# icc_reva_me30 register map
Registers are 32-bit, access not given, no defined reset value unless marked. A register's access mark holds for its fields unless they carry their own. Offsets are from the block's base; lines under a group give offsets from that group; [hi:lo] are bit positions; {n}, {i} and the like mark numbered series; 'fields as' and 'values as' point back to an identical list; <NAME> marks a mode.

## Memory map
0x4002A000 ICC size 0x1000 — Instruction Cache Controller Registers

## ICC — Instruction Cache Controller Registers
Base 0x4002A000
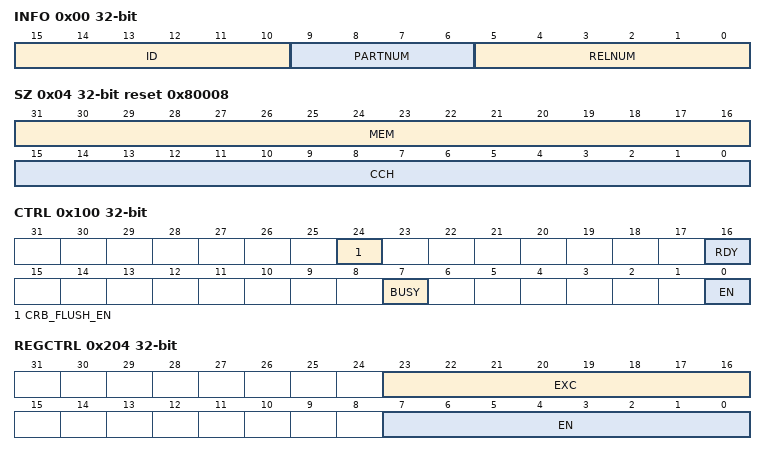
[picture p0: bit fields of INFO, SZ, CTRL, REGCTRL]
0x00 INFO ro — Cache ID Register.
  [15:10] ID — Cache ID. This field reflects the value of the C_ID_CACHEID configuration parameter.
  [9:6] PARTNUM — Part Number. This field reflects the value of C_ID_PART_NUMBER configuration parameter.
  [5:0] RELNUM — Release Number. Identifies the RTL release version.
0x04 SZ ro reset 0x80008 — Memory Configuration Register.
  [31:16] MEM — Main Memory Size. Indicates the total size, in units of 128 Kbytes, of code memory accessible to the cache controller.
  [15:0] CCH — Cache Size. Indicates total size in Kbytes of cache.
0x100 CTRL — Cache Control and Status Register.
  [24] CRB_FLUSH_EN — Coherent Read Buffer flush enable. Write 1 to flush the coherent read buffer.
  [16] RDY ro — Cache Ready flag. Cleared by hardware when at any time the cache as a whole is invalidated (including a system reset). When this bit is 0, the cache is effectively in bypass mode (instruction fetches will come from main memory or from the line fill buffer). Set by hardware when the invalidate operation is complete and the cache is ready.
    0=notReady; 1=ready
  [7] BUSY ro — Cache Busy. Read-only status bit set by hardware while a cache operation (invalidate or flush) is in progress.
  [0] EN — Cache Enable. Controls whether the cache is bypassed or is in use. Changing the state of this bit will cause the instruction cache to be flushed and its contents invalidated.
    0=dis (Cache Bypassed. Instruction data is stored in the line fill buffer but is not written to main cache memory array.); 1=en (Cache Enabled.)
0x200 WAY — Cache Way Control Register.
  [2:0] WAY — Number of cache way, default is always 2. Allowed values are 1,2,4.
0x204 REGCTRL — Regional Control Register.
  [23:16] EXC — Cache the data only if the TAG content is excluded in the high and low bound.
  [7:0] EN — Enable the regional high andlow bound compare, cache the data only if the TAG content between the high and low bound.
{0x208+8i} REGION[{i}] (i=0..3) group — Regional Low and High Bound Registers.
  0x00 LBOUND rw — Regional Low Bound Register.
    [31:0] BOUND — Low Bound.
  0x04 HBOUND rw — Regional High Bound Register.
    [31:0] BOUND — High Bound.
0x300 PFMCTRL — Performance Control Register.
  [0] EN — Enable performance counter. Clear to 0 when AHB access counter reach 0.
0x304 PFMCNT — Performance Counter Register.
  [31:0] CNT — Write the total AHB access counter. Read the current performance hit count.
0x700 INVALIDATE rw — Invalidate All Registers.
  [31:0] INVALID — Invalidate.
